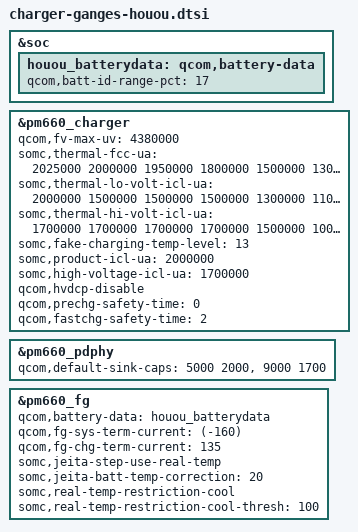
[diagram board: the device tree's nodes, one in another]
/* Copyright (c) 2015-2017, The Linux Foundation. All rights reserved.
 *
 * This program is free software; you can redistribute it and/or modify
 * it under the terms of the GNU General Public License version 2 and
 * only version 2 as published by the Free Software Foundation.
 *
 * This program is distributed in the hope that it will be useful,
 * but WITHOUT ANY WARRANTY; without even the implied warranty of
 * MERCHANTABILITY or FITNESS FOR A PARTICULAR PURPOSE.  See the
 * GNU General Public License for more details.
 */
/*
 * Copyright (C) 2018 Sony Mobile Communications Inc.
 *
 * This program is free software; you can redistribute it and/or modify
 * it under the terms of the GNU General Public License version 2, as
 * published by the Free Software Foundation.
 */
/*
 * Copyright (C) 2018 Sony Mobile Communications Inc.
 *
 * This program is free software; you can redistribute it and/or modify
 * it under the terms of the GNU General Public License version 2, as
 * published by the Free Software Foundation.
 */

&soc {
	houou_batterydata: qcom,battery-data {
		qcom,batt-id-range-pct = <17>;
		#include "fg-gen3-batterydata-houou-send-4245mv-2425mah.dtsi"
		#include "fg-gen3-batterydata-houou-send-4297mv-2539mah.dtsi"
		#include "fg-gen3-batterydata-houou-send-4335mv-2647mah.dtsi"
		#include "fg-gen3-batterydata-houou-send-4380mv-2729mah.dtsi"
	};
};

&pm660_charger {
	qcom,fv-max-uv = <4380000>;
	somc,thermal-fcc-ua = <2025000 2000000 1950000
				1800000 1500000 1300000
				1300000 1000000 800000
				700000 700000 500000
				300000 100000 0>;
	somc,thermal-lo-volt-icl-ua = <2000000 1500000 1500000
					1500000 1300000 1100000
					1100000 1000000 900000
					900000 900000 500000
					200000 100000 0>;
	somc,thermal-hi-volt-icl-ua = <1700000 1700000 1700000
					1700000 1500000 1000000
					1000000 1000000 1000000
					1000000 600000 500000
					200000 100000 0>;
	somc,fake-charging-temp-level = <13>;
	somc,product-icl-ua = <2000000>;
	somc,high-voltage-icl-ua = <1700000>;
	qcom,hvdcp-disable;
	qcom,prechg-safety-time = <0>;
	qcom,fastchg-safety-time = <2>;
};

&pm660_pdphy {
	qcom,default-sink-caps = <5000 2000>, /* 5V @ 2A */
				 <9000 1700>; /* 9V @ 1.7A */
};

&pm660_fg {
	qcom,battery-data = <&houou_batterydata>;
	qcom,fg-sys-term-current = <(-160)>;
	qcom,fg-chg-term-current = <135>;
	somc,jeita-step-use-real-temp;
	somc,jeita-batt-temp-correction = <20>;
	somc,real-temp-restriction-cool;
	somc,real-temp-restriction-cool-thresh = <100>;
};
